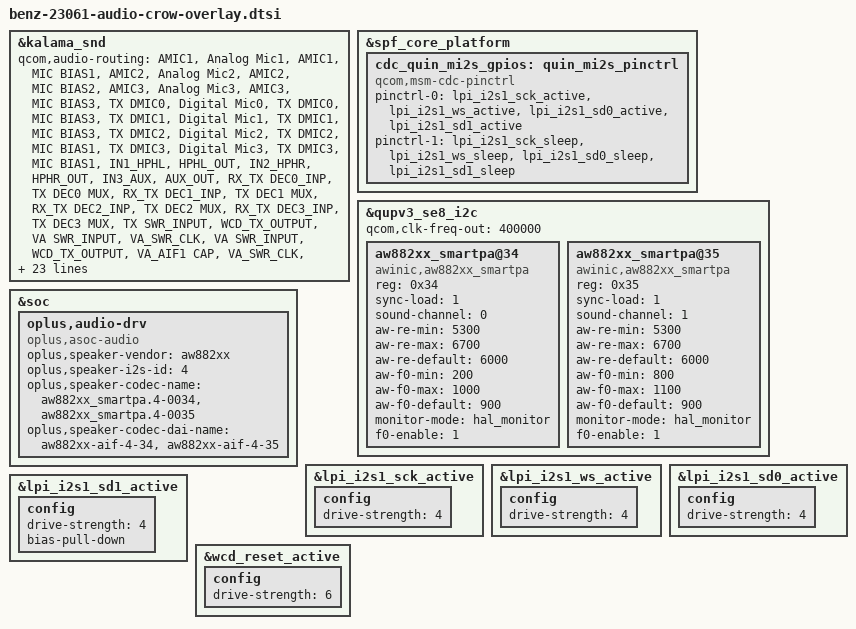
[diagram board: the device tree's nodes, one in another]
&kalama_snd {
	qcom,audio-routing =
		"AMIC1", "Analog Mic1",
		"AMIC1", "MIC BIAS1",
		"AMIC2", "Analog Mic2",
		"AMIC2", "MIC BIAS2",
		"AMIC3", "Analog Mic3",
		"AMIC3", "MIC BIAS3",
		"TX DMIC0", "Digital Mic0",
		"TX DMIC0", "MIC BIAS3",
		"TX DMIC1", "Digital Mic1",
		"TX DMIC1", "MIC BIAS3",
		"TX DMIC2", "Digital Mic2",
		"TX DMIC2", "MIC BIAS1",
		"TX DMIC3", "Digital Mic3",
		"TX DMIC3", "MIC BIAS1",
		"IN1_HPHL", "HPHL_OUT",
		"IN2_HPHR", "HPHR_OUT",
		"IN3_AUX", "AUX_OUT",
		"RX_TX DEC0_INP", "TX DEC0 MUX",
		"RX_TX DEC1_INP", "TX DEC1 MUX",
		"RX_TX DEC2_INP", "TX DEC2 MUX",
		"RX_TX DEC3_INP", "TX DEC3 MUX",
		"TX SWR_INPUT", "WCD_TX_OUTPUT",
		"VA SWR_INPUT", "VA_SWR_CLK",
		"VA SWR_INPUT", "WCD_TX_OUTPUT",
		"VA_AIF1 CAP", "VA_SWR_CLK",
		"VA_AIF2 CAP", "VA_SWR_CLK",
		"VA_AIF3 CAP", "VA_SWR_CLK",
		"VA DMIC0", "Digital Mic0",
		"VA DMIC1", "Digital Mic1",
		"VA DMIC2", "Digital Mic2",
		"VA DMIC3", "Digital Mic3",
		"VA DMIC0", "VA MIC BIAS3",
		"VA DMIC1", "VA MIC BIAS3",
		"VA DMIC2", "VA MIC BIAS1",
		"VA DMIC3", "VA MIC BIAS1";

	qcom,mi2s-audio-intf = <1>;
	qcom,tdm-audio-intf = <0>;
	qcom,auxpcm-audio-intf = <0>;

	qcom,quin-mi2s-gpios = <&cdc_quin_mi2s_gpios>;

	qcom,msm-mbhc-usbc-audio-supported = <1>;
	qcom,msm-mbhc-hs-mic-max-threshold-mv = <2600>;
	qcom,msm-mbhc-hs-mic-min-threshold-mv = <112>; /* 75*2700/1800 */
	qcom,msm-mbhc-hphl-swh = <0>;
	qcom,msm-mbhc-gnd-swh = <0>;
	oplus,mbhc-headset-micbias-alwayon = <1>;
	oplus,mbhc-check-cross-conn = <1>;
	asoc-codec  = <&stub_codec>, <&lpass_cdc>,
		      <&wcd937x_codec>;
	asoc-codec-names = "msm-stub-codec.1", "lpass-cdc",
			   "wcd937x_codec";
	qcom,wsa-max-devs = <0>;
};

&spf_core_platform {
	cdc_quin_mi2s_gpios: quin_mi2s_pinctrl {
		status = "ok";
		compatible = "qcom,msm-cdc-pinctrl";
		pinctrl-names = "aud_active", "aud_sleep";
		pinctrl-0 = <&lpi_i2s1_sck_active &lpi_i2s1_ws_active
				&lpi_i2s1_sd0_active &lpi_i2s1_sd1_active>;
		pinctrl-1 = <&lpi_i2s1_sck_sleep &lpi_i2s1_ws_sleep
				&lpi_i2s1_sd0_sleep &lpi_i2s1_sd1_sleep>;
		#gpio-cells = <0>;
	};
};

&qupv3_se8_i2c {
	status = "ok";
	qcom,clk-freq-out = <400000>;
	aw882xx_smartpa@34 {
		compatible = "awinic,aw882xx_smartpa";
		reg = <0x34>;
		//reset-gpio = <&tlmm 84 0>;
		//irq-gpio = <&tlmm 136 0x2008>;
		sync-load = <1>;
		sound-channel = <0>;
		aw-re-min = <5300>;
		aw-re-max = <6700>;
		aw-re-default = <6000>;
		aw-f0-min = <200>;
		aw-f0-max = <1000>;
		aw-f0-default = <900>;
		//aw-cali-mode = "none";
		monitor-mode = "hal_monitor";
		f0-enable = <1>;
		status = "okay";
	};

	aw882xx_smartpa@35 {
		compatible = "awinic,aw882xx_smartpa";
		reg = <0x35>;
		//reset-gpio = <&tlmm 82 0>;
		//irq-gpio = <&tlmm 143 0x2008>;
		sync-load = <1>;
		sound-channel = <1>;
		aw-re-min = <5300>;
		aw-re-max = <6700>;
		aw-re-default = <6000>;
		aw-f0-min = <800>;
		aw-f0-max = <1100>;
		aw-f0-default = <900>;
		//aw-cali-mode = "none";
		monitor-mode = "hal_monitor";
		f0-enable = <1>;
		status = "okay";
	};
};

&soc {
	oplus,audio-drv {
		compatible = "oplus,asoc-audio";
		//for aw882xx speaker
		oplus,speaker-vendor = "aw882xx";
		oplus,speaker-i2s-id = <4>;
		oplus,speaker-codec-name = "aw882xx_smartpa.4-0034", "aw882xx_smartpa.4-0035";
		oplus,speaker-codec-dai-name = "aw882xx-aif-4-34", "aw882xx-aif-4-35";
	};
};

&lpi_i2s1_sck_active {
	config {
		drive-strength = <4>;   /* 4 mA */
	};
};

&lpi_i2s1_ws_active {
	config {
		drive-strength = <4>;   /* 4 mA */
	};
};

&lpi_i2s1_sd0_active {
	config {
		drive-strength = <4>;   /* 4 mA */
	};
};

&lpi_i2s1_sd1_active {
	config {
		drive-strength = <4>;   /* 4 mA */
		bias-pull-down;
	};
};

&wcd_reset_active {
	config {
		drive-strength = <6>;  /* 6 mA */
	};
};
